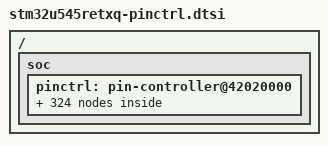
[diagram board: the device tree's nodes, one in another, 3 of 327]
/*
 * NOTE: Autogenerated file using genpinctrl.py
 *
 * SPDX-License-Identifier: Apache-2.0
 */

#include <zephyr/dt-bindings/pinctrl/stm32-pinctrl.h>

/ {
	soc {
		pinctrl: pin-controller@42020000 {

			/* ADC_IN / ADC_INN / ADC_INP */

			/omit-if-no-ref/ adc1_in5_pa0: adc1_in5_pa0 {
				pinmux = <STM32_PINMUX('A', 0, ANALOG)>;
			};

			/omit-if-no-ref/ adc1_in6_pa1: adc1_in6_pa1 {
				pinmux = <STM32_PINMUX('A', 1, ANALOG)>;
			};

			/omit-if-no-ref/ adc1_in7_pa2: adc1_in7_pa2 {
				pinmux = <STM32_PINMUX('A', 2, ANALOG)>;
			};

			/omit-if-no-ref/ adc1_in8_pa3: adc1_in8_pa3 {
				pinmux = <STM32_PINMUX('A', 3, ANALOG)>;
			};

			/omit-if-no-ref/ adc1_in9_pa4: adc1_in9_pa4 {
				pinmux = <STM32_PINMUX('A', 4, ANALOG)>;
			};

			/omit-if-no-ref/ adc1_in10_pa5: adc1_in10_pa5 {
				pinmux = <STM32_PINMUX('A', 5, ANALOG)>;
			};

			/omit-if-no-ref/ adc1_in11_pa6: adc1_in11_pa6 {
				pinmux = <STM32_PINMUX('A', 6, ANALOG)>;
			};

			/omit-if-no-ref/ adc1_in12_pa7: adc1_in12_pa7 {
				pinmux = <STM32_PINMUX('A', 7, ANALOG)>;
			};

			/omit-if-no-ref/ adc1_in15_pb0: adc1_in15_pb0 {
				pinmux = <STM32_PINMUX('B', 0, ANALOG)>;
			};

			/omit-if-no-ref/ adc1_in16_pb1: adc1_in16_pb1 {
				pinmux = <STM32_PINMUX('B', 1, ANALOG)>;
			};

			/omit-if-no-ref/ adc1_in17_pb2: adc1_in17_pb2 {
				pinmux = <STM32_PINMUX('B', 2, ANALOG)>;
			};

			/omit-if-no-ref/ adc1_in1_pc0: adc1_in1_pc0 {
				pinmux = <STM32_PINMUX('C', 0, ANALOG)>;
			};

			/omit-if-no-ref/ adc1_in2_pc1: adc1_in2_pc1 {
				pinmux = <STM32_PINMUX('C', 1, ANALOG)>;
			};

			/omit-if-no-ref/ adc1_in3_pc2: adc1_in3_pc2 {
				pinmux = <STM32_PINMUX('C', 2, ANALOG)>;
			};

			/omit-if-no-ref/ adc1_in4_pc3: adc1_in4_pc3 {
				pinmux = <STM32_PINMUX('C', 3, ANALOG)>;
			};

			/omit-if-no-ref/ adc4_in9_pa4: adc4_in9_pa4 {
				pinmux = <STM32_PINMUX('A', 4, ANALOG)>;
			};

			/omit-if-no-ref/ adc4_in10_pa5: adc4_in10_pa5 {
				pinmux = <STM32_PINMUX('A', 5, ANALOG)>;
			};

			/omit-if-no-ref/ adc4_in11_pa6: adc4_in11_pa6 {
				pinmux = <STM32_PINMUX('A', 6, ANALOG)>;
			};

			/omit-if-no-ref/ adc4_in20_pa7: adc4_in20_pa7 {
				pinmux = <STM32_PINMUX('A', 7, ANALOG)>;
			};

			/omit-if-no-ref/ adc4_in18_pb0: adc4_in18_pb0 {
				pinmux = <STM32_PINMUX('B', 0, ANALOG)>;
			};

			/omit-if-no-ref/ adc4_in19_pb1: adc4_in19_pb1 {
				pinmux = <STM32_PINMUX('B', 1, ANALOG)>;
			};

			/omit-if-no-ref/ adc4_in1_pc0: adc4_in1_pc0 {
				pinmux = <STM32_PINMUX('C', 0, ANALOG)>;
			};

			/omit-if-no-ref/ adc4_in2_pc1: adc4_in2_pc1 {
				pinmux = <STM32_PINMUX('C', 1, ANALOG)>;
			};

			/omit-if-no-ref/ adc4_in3_pc2: adc4_in3_pc2 {
				pinmux = <STM32_PINMUX('C', 2, ANALOG)>;
			};

			/omit-if-no-ref/ adc4_in4_pc3: adc4_in4_pc3 {
				pinmux = <STM32_PINMUX('C', 3, ANALOG)>;
			};

			/* Analog */

			/omit-if-no-ref/ analog_pa0: analog_pa0 {
				pinmux = <STM32_PINMUX('A', 0, ANALOG)>;
			};

			/omit-if-no-ref/ analog_pa1: analog_pa1 {
				pinmux = <STM32_PINMUX('A', 1, ANALOG)>;
			};

			/omit-if-no-ref/ analog_pa2: analog_pa2 {
				pinmux = <STM32_PINMUX('A', 2, ANALOG)>;
			};

			/omit-if-no-ref/ analog_pa3: analog_pa3 {
				pinmux = <STM32_PINMUX('A', 3, ANALOG)>;
			};

			/omit-if-no-ref/ analog_pa4: analog_pa4 {
				pinmux = <STM32_PINMUX('A', 4, ANALOG)>;
			};

			/omit-if-no-ref/ analog_pa5: analog_pa5 {
				pinmux = <STM32_PINMUX('A', 5, ANALOG)>;
			};

			/omit-if-no-ref/ analog_pa6: analog_pa6 {
				pinmux = <STM32_PINMUX('A', 6, ANALOG)>;
			};

			/omit-if-no-ref/ analog_pa7: analog_pa7 {
				pinmux = <STM32_PINMUX('A', 7, ANALOG)>;
			};

			/omit-if-no-ref/ analog_pa8: analog_pa8 {
				pinmux = <STM32_PINMUX('A', 8, ANALOG)>;
			};

			/omit-if-no-ref/ analog_pa9: analog_pa9 {
				pinmux = <STM32_PINMUX('A', 9, ANALOG)>;
			};

			/omit-if-no-ref/ analog_pa10: analog_pa10 {
				pinmux = <STM32_PINMUX('A', 10, ANALOG)>;
			};

			/omit-if-no-ref/ analog_pa11: analog_pa11 {
				pinmux = <STM32_PINMUX('A', 11, ANALOG)>;
			};

			/omit-if-no-ref/ analog_pa12: analog_pa12 {
				pinmux = <STM32_PINMUX('A', 12, ANALOG)>;
			};

			/omit-if-no-ref/ analog_pa13: analog_pa13 {
				pinmux = <STM32_PINMUX('A', 13, ANALOG)>;
			};

			/omit-if-no-ref/ analog_pa14: analog_pa14 {
				pinmux = <STM32_PINMUX('A', 14, ANALOG)>;
			};

			/omit-if-no-ref/ analog_pa15: analog_pa15 {
				pinmux = <STM32_PINMUX('A', 15, ANALOG)>;
			};

			/omit-if-no-ref/ analog_pb0: analog_pb0 {
				pinmux = <STM32_PINMUX('B', 0, ANALOG)>;
			};

			/omit-if-no-ref/ analog_pb1: analog_pb1 {
				pinmux = <STM32_PINMUX('B', 1, ANALOG)>;
			};

			/omit-if-no-ref/ analog_pb2: analog_pb2 {
				pinmux = <STM32_PINMUX('B', 2, ANALOG)>;
			};

			/omit-if-no-ref/ analog_pb3: analog_pb3 {
				pinmux = <STM32_PINMUX('B', 3, ANALOG)>;
			};

			/omit-if-no-ref/ analog_pb4: analog_pb4 {
				pinmux = <STM32_PINMUX('B', 4, ANALOG)>;
			};

			/omit-if-no-ref/ analog_pb5: analog_pb5 {
				pinmux = <STM32_PINMUX('B', 5, ANALOG)>;
			};

			/omit-if-no-ref/ analog_pb6: analog_pb6 {
				pinmux = <STM32_PINMUX('B', 6, ANALOG)>;
			};

			/omit-if-no-ref/ analog_pb7: analog_pb7 {
				pinmux = <STM32_PINMUX('B', 7, ANALOG)>;
			};

			/omit-if-no-ref/ analog_pb8: analog_pb8 {
				pinmux = <STM32_PINMUX('B', 8, ANALOG)>;
			};

			/omit-if-no-ref/ analog_pb10: analog_pb10 {
				pinmux = <STM32_PINMUX('B', 10, ANALOG)>;
			};

			/omit-if-no-ref/ analog_pb13: analog_pb13 {
				pinmux = <STM32_PINMUX('B', 13, ANALOG)>;
			};

			/omit-if-no-ref/ analog_pb14: analog_pb14 {
				pinmux = <STM32_PINMUX('B', 14, ANALOG)>;
			};

			/omit-if-no-ref/ analog_pb15: analog_pb15 {
				pinmux = <STM32_PINMUX('B', 15, ANALOG)>;
			};

			/omit-if-no-ref/ analog_pc0: analog_pc0 {
				pinmux = <STM32_PINMUX('C', 0, ANALOG)>;
			};

			/omit-if-no-ref/ analog_pc1: analog_pc1 {
				pinmux = <STM32_PINMUX('C', 1, ANALOG)>;
			};

			/omit-if-no-ref/ analog_pc2: analog_pc2 {
				pinmux = <STM32_PINMUX('C', 2, ANALOG)>;
			};

			/omit-if-no-ref/ analog_pc3: analog_pc3 {
				pinmux = <STM32_PINMUX('C', 3, ANALOG)>;
			};

			/omit-if-no-ref/ analog_pc6: analog_pc6 {
				pinmux = <STM32_PINMUX('C', 6, ANALOG)>;
			};

			/omit-if-no-ref/ analog_pc7: analog_pc7 {
				pinmux = <STM32_PINMUX('C', 7, ANALOG)>;
			};

			/omit-if-no-ref/ analog_pc8: analog_pc8 {
				pinmux = <STM32_PINMUX('C', 8, ANALOG)>;
			};

			/omit-if-no-ref/ analog_pc9: analog_pc9 {
				pinmux = <STM32_PINMUX('C', 9, ANALOG)>;
			};

			/omit-if-no-ref/ analog_pc10: analog_pc10 {
				pinmux = <STM32_PINMUX('C', 10, ANALOG)>;
			};

			/omit-if-no-ref/ analog_pc11: analog_pc11 {
				pinmux = <STM32_PINMUX('C', 11, ANALOG)>;
			};

			/omit-if-no-ref/ analog_pc12: analog_pc12 {
				pinmux = <STM32_PINMUX('C', 12, ANALOG)>;
			};

			/omit-if-no-ref/ analog_pc13: analog_pc13 {
				pinmux = <STM32_PINMUX('C', 13, ANALOG)>;
			};

			/omit-if-no-ref/ analog_pc14: analog_pc14 {
				pinmux = <STM32_PINMUX('C', 14, ANALOG)>;
			};

			/omit-if-no-ref/ analog_pc15: analog_pc15 {
				pinmux = <STM32_PINMUX('C', 15, ANALOG)>;
			};

			/omit-if-no-ref/ analog_pd2: analog_pd2 {
				pinmux = <STM32_PINMUX('D', 2, ANALOG)>;
			};

			/omit-if-no-ref/ analog_ph0: analog_ph0 {
				pinmux = <STM32_PINMUX('H', 0, ANALOG)>;
			};

			/omit-if-no-ref/ analog_ph1: analog_ph1 {
				pinmux = <STM32_PINMUX('H', 1, ANALOG)>;
			};

			/omit-if-no-ref/ analog_ph3: analog_ph3 {
				pinmux = <STM32_PINMUX('H', 3, ANALOG)>;
			};

			/* COMP_IN */

			/omit-if-no-ref/ comp1_inp_pa2: comp1_inp_pa2 {
				pinmux = <STM32_PINMUX('A', 2, ANALOG)>;
			};

			/omit-if-no-ref/ comp1_inm_pb1: comp1_inm_pb1 {
				pinmux = <STM32_PINMUX('B', 1, ANALOG)>;
			};

			/omit-if-no-ref/ comp1_inp_pb2: comp1_inp_pb2 {
				pinmux = <STM32_PINMUX('B', 2, ANALOG)>;
			};

			/omit-if-no-ref/ comp1_inp_pb3: comp1_inp_pb3 {
				pinmux = <STM32_PINMUX('B', 3, ANALOG)>;
			};

			/omit-if-no-ref/ comp1_inp_pb4: comp1_inp_pb4 {
				pinmux = <STM32_PINMUX('B', 4, ANALOG)>;
			};

			/omit-if-no-ref/ comp1_inp_pb6: comp1_inp_pb6 {
				pinmux = <STM32_PINMUX('B', 6, ANALOG)>;
			};

			/* COMP_OUT */

			/omit-if-no-ref/ comp1_out_pb0: comp1_out_pb0 {
				pinmux = <STM32_PINMUX('B', 0, AF12)>;
			};

			/omit-if-no-ref/ comp1_out_pb10: comp1_out_pb10 {
				pinmux = <STM32_PINMUX('B', 10, AF12)>;
			};

			/* DAC_OUT */

			/omit-if-no-ref/ dac1_out1_pa4: dac1_out1_pa4 {
				pinmux = <STM32_PINMUX('A', 4, ANALOG)>;
			};

			/omit-if-no-ref/ dac1_out2_pa5: dac1_out2_pa5 {
				pinmux = <STM32_PINMUX('A', 5, ANALOG)>;
			};

			/* FDCAN_RX */

			/omit-if-no-ref/ fdcan1_rx_pa11: fdcan1_rx_pa11 {
				pinmux = <STM32_PINMUX('A', 11, AF9)>;
			};

			/omit-if-no-ref/ fdcan1_rx_pb8: fdcan1_rx_pb8 {
				pinmux = <STM32_PINMUX('B', 8, AF9)>;
			};

			/* FDCAN_TX */

			/omit-if-no-ref/ fdcan1_tx_pa12: fdcan1_tx_pa12 {
				pinmux = <STM32_PINMUX('A', 12, AF9)>;
			};

			/* I2C_SCL */

			/omit-if-no-ref/ i2c1_scl_pb6: i2c1_scl_pb6 {
				pinmux = <STM32_PINMUX('B', 6, AF4)>;
				bias-pull-up;
				drive-open-drain;
			};

			/omit-if-no-ref/ i2c1_scl_pb8: i2c1_scl_pb8 {
				pinmux = <STM32_PINMUX('B', 8, AF4)>;
				bias-pull-up;
				drive-open-drain;
			};

			/omit-if-no-ref/ i2c2_scl_pb10: i2c2_scl_pb10 {
				pinmux = <STM32_PINMUX('B', 10, AF4)>;
				bias-pull-up;
				drive-open-drain;
			};

			/omit-if-no-ref/ i2c2_scl_pb13: i2c2_scl_pb13 {
				pinmux = <STM32_PINMUX('B', 13, AF4)>;
				bias-pull-up;
				drive-open-drain;
			};

			/omit-if-no-ref/ i2c3_scl_pa7: i2c3_scl_pa7 {
				pinmux = <STM32_PINMUX('A', 7, AF4)>;
				bias-pull-up;
				drive-open-drain;
			};

			/omit-if-no-ref/ i2c3_scl_pc0: i2c3_scl_pc0 {
				pinmux = <STM32_PINMUX('C', 0, AF4)>;
				bias-pull-up;
				drive-open-drain;
			};

			/omit-if-no-ref/ i2c4_scl_pb6: i2c4_scl_pb6 {
				pinmux = <STM32_PINMUX('B', 6, AF5)>;
				bias-pull-up;
				drive-open-drain;
			};

			/omit-if-no-ref/ i2c4_scl_pb10: i2c4_scl_pb10 {
				pinmux = <STM32_PINMUX('B', 10, AF3)>;
				bias-pull-up;
				drive-open-drain;
			};

			/* I2C_SDA */

			/omit-if-no-ref/ i2c1_sda_pb3: i2c1_sda_pb3 {
				pinmux = <STM32_PINMUX('B', 3, AF4)>;
				bias-pull-up;
				drive-open-drain;
			};

			/omit-if-no-ref/ i2c1_sda_pb7: i2c1_sda_pb7 {
				pinmux = <STM32_PINMUX('B', 7, AF4)>;
				bias-pull-up;
				drive-open-drain;
			};

			/omit-if-no-ref/ i2c2_sda_pb14: i2c2_sda_pb14 {
				pinmux = <STM32_PINMUX('B', 14, AF4)>;
				bias-pull-up;
				drive-open-drain;
			};

			/omit-if-no-ref/ i2c3_sda_pb4: i2c3_sda_pb4 {
				pinmux = <STM32_PINMUX('B', 4, AF4)>;
				bias-pull-up;
				drive-open-drain;
			};

			/omit-if-no-ref/ i2c3_sda_pc1: i2c3_sda_pc1 {
				pinmux = <STM32_PINMUX('C', 1, AF4)>;
				bias-pull-up;
				drive-open-drain;
			};

			/omit-if-no-ref/ i2c4_sda_pb7: i2c4_sda_pb7 {
				pinmux = <STM32_PINMUX('B', 7, AF5)>;
				bias-pull-up;
				drive-open-drain;
			};

			/* I2C_SMBA */

			/omit-if-no-ref/ i2c1_smba_pa1: i2c1_smba_pa1 {
				pinmux = <STM32_PINMUX('A', 1, AF4)>;
				bias-pull-up;
			};

			/omit-if-no-ref/ i2c1_smba_pa14: i2c1_smba_pa14 {
				pinmux = <STM32_PINMUX('A', 14, AF4)>;
				bias-pull-up;
			};

			/omit-if-no-ref/ i2c1_smba_pb5: i2c1_smba_pb5 {
				pinmux = <STM32_PINMUX('B', 5, AF4)>;
				bias-pull-up;
			};

			/omit-if-no-ref/ i2c3_smba_pb2: i2c3_smba_pb2 {
				pinmux = <STM32_PINMUX('B', 2, AF4)>;
				bias-pull-up;
			};

			/omit-if-no-ref/ i2c4_smba_pa14: i2c4_smba_pa14 {
				pinmux = <STM32_PINMUX('A', 14, AF5)>;
				bias-pull-up;
			};

			/* JTAG PORT */

			/omit-if-no-ref/ debug_jtms_swdio_pa13: debug_jtms_swdio_pa13 {
				pinmux = <STM32_PINMUX('A', 13, AF0)>;
			};

			/omit-if-no-ref/ debug_jtck_swclk_pa14: debug_jtck_swclk_pa14 {
				pinmux = <STM32_PINMUX('A', 14, AF0)>;
			};

			/omit-if-no-ref/ debug_jtdi_pa15: debug_jtdi_pa15 {
				pinmux = <STM32_PINMUX('A', 15, AF0)>;
			};

			/omit-if-no-ref/ debug_jtdo_swo_pb3: debug_jtdo_swo_pb3 {
				pinmux = <STM32_PINMUX('B', 3, AF0)>;
			};

			/omit-if-no-ref/ debug_jtrst_pb4: debug_jtrst_pb4 {
				pinmux = <STM32_PINMUX('B', 4, AF0)>;
			};

			/* OCTOSPI */

			/omit-if-no-ref/ octospi1_ncs_pa0: octospi1_ncs_pa0 {
				pinmux = <STM32_PINMUX('A', 0, AF10)>;
				slew-rate = "very-high-speed";
			};

			/omit-if-no-ref/ octospi1_dqs_pa1: octospi1_dqs_pa1 {
				pinmux = <STM32_PINMUX('A', 1, AF10)>;
				slew-rate = "very-high-speed";
			};

			/omit-if-no-ref/ octospi1_ncs_pa2: octospi1_ncs_pa2 {
				pinmux = <STM32_PINMUX('A', 2, AF10)>;
				slew-rate = "very-high-speed";
			};

			/omit-if-no-ref/ octospi1_clk_pa3: octospi1_clk_pa3 {
				pinmux = <STM32_PINMUX('A', 3, AF10)>;
				slew-rate = "very-high-speed";
			};

			/omit-if-no-ref/ octospi1_ncs_pa4: octospi1_ncs_pa4 {
				pinmux = <STM32_PINMUX('A', 4, AF3)>;
				slew-rate = "very-high-speed";
			};

			/omit-if-no-ref/ octospi1_io3_pa6: octospi1_io3_pa6 {
				pinmux = <STM32_PINMUX('A', 6, AF10)>;
				slew-rate = "very-high-speed";
			};

			/omit-if-no-ref/ octospi1_io2_pa7: octospi1_io2_pa7 {
				pinmux = <STM32_PINMUX('A', 7, AF10)>;
				slew-rate = "very-high-speed";
			};

			/omit-if-no-ref/ octospi1_ncs_pa12: octospi1_ncs_pa12 {
				pinmux = <STM32_PINMUX('A', 12, AF6)>;
				slew-rate = "very-high-speed";
			};

			/omit-if-no-ref/ octospi1_io1_pb0: octospi1_io1_pb0 {
				pinmux = <STM32_PINMUX('B', 0, AF10)>;
				slew-rate = "very-high-speed";
			};

			/omit-if-no-ref/ octospi1_io0_pb1: octospi1_io0_pb1 {
				pinmux = <STM32_PINMUX('B', 1, AF10)>;
				slew-rate = "very-high-speed";
			};

			/omit-if-no-ref/ octospi1_dqs_pb2: octospi1_dqs_pb2 {
				pinmux = <STM32_PINMUX('B', 2, AF10)>;
				slew-rate = "very-high-speed";
			};

			/omit-if-no-ref/ octospi1_nclk_pb5: octospi1_nclk_pb5 {
				pinmux = <STM32_PINMUX('B', 5, AF3)>;
				slew-rate = "very-high-speed";
			};

			/omit-if-no-ref/ octospi1_clk_pb10: octospi1_clk_pb10 {
				pinmux = <STM32_PINMUX('B', 10, AF10)>;
				slew-rate = "very-high-speed";
			};

			/omit-if-no-ref/ octospi1_io7_pc0: octospi1_io7_pc0 {
				pinmux = <STM32_PINMUX('C', 0, AF3)>;
				slew-rate = "very-high-speed";
			};

			/omit-if-no-ref/ octospi1_io4_pc1: octospi1_io4_pc1 {
				pinmux = <STM32_PINMUX('C', 1, AF10)>;
				slew-rate = "very-high-speed";
			};

			/omit-if-no-ref/ octospi1_io5_pc2: octospi1_io5_pc2 {
				pinmux = <STM32_PINMUX('C', 2, AF10)>;
				slew-rate = "very-high-speed";
			};

			/omit-if-no-ref/ octospi1_io6_pc3: octospi1_io6_pc3 {
				pinmux = <STM32_PINMUX('C', 3, AF10)>;
				slew-rate = "very-high-speed";
			};

			/omit-if-no-ref/ octospi1_ncs_pc11: octospi1_ncs_pc11 {
				pinmux = <STM32_PINMUX('C', 11, AF5)>;
				slew-rate = "very-high-speed";
			};

			/* OPAMP */

			/omit-if-no-ref/ opamp1_vinp_pa0: opamp1_vinp_pa0 {
				pinmux = <STM32_PINMUX('A', 0, ANALOG)>;
			};

			/omit-if-no-ref/ opamp1_vinm_pa1: opamp1_vinm_pa1 {
				pinmux = <STM32_PINMUX('A', 1, ANALOG)>;
			};

			/omit-if-no-ref/ opamp1_vout_pa3: opamp1_vout_pa3 {
				pinmux = <STM32_PINMUX('A', 3, ANALOG)>;
			};

			/* RCC_MCO */

			/omit-if-no-ref/ rcc_mco_pa8: rcc_mco_pa8 {
				pinmux = <STM32_PINMUX('A', 8, AF0)>;
				slew-rate = "very-high-speed";
			};

			/* SAI */

			/omit-if-no-ref/ sai1_ck1_pa3: sai1_ck1_pa3 {
				pinmux = <STM32_PINMUX('A', 3, AF3)>;
			};

			/omit-if-no-ref/ sai1_mclk_a_pa3: sai1_mclk_a_pa3 {
				pinmux = <STM32_PINMUX('A', 3, AF13)>;
			};

			/omit-if-no-ref/ sai1_fs_b_pa4: sai1_fs_b_pa4 {
				pinmux = <STM32_PINMUX('A', 4, AF13)>;
			};

			/omit-if-no-ref/ sai1_ck2_pa8: sai1_ck2_pa8 {
				pinmux = <STM32_PINMUX('A', 8, AF3)>;
			};

			/omit-if-no-ref/ sai1_sck_a_pa8: sai1_sck_a_pa8 {
				pinmux = <STM32_PINMUX('A', 8, AF13)>;
			};

			/omit-if-no-ref/ sai1_fs_a_pa9: sai1_fs_a_pa9 {
				pinmux = <STM32_PINMUX('A', 9, AF13)>;
			};

			/omit-if-no-ref/ sai1_d1_pa10: sai1_d1_pa10 {
				pinmux = <STM32_PINMUX('A', 10, AF3)>;
			};

			/omit-if-no-ref/ sai1_sd_a_pa10: sai1_sd_a_pa10 {
				pinmux = <STM32_PINMUX('A', 10, AF13)>;
			};

			/omit-if-no-ref/ sai1_sd_b_pa13: sai1_sd_b_pa13 {
				pinmux = <STM32_PINMUX('A', 13, AF13)>;
			};

			/omit-if-no-ref/ sai1_fs_b_pa14: sai1_fs_b_pa14 {
				pinmux = <STM32_PINMUX('A', 14, AF13)>;
			};

			/omit-if-no-ref/ sai1_sck_b_pb3: sai1_sck_b_pb3 {
				pinmux = <STM32_PINMUX('B', 3, AF13)>;
			};

			/omit-if-no-ref/ sai1_mclk_b_pb4: sai1_mclk_b_pb4 {
				pinmux = <STM32_PINMUX('B', 4, AF13)>;
			};

			/omit-if-no-ref/ sai1_sd_b_pb5: sai1_sd_b_pb5 {
				pinmux = <STM32_PINMUX('B', 5, AF13)>;
			};

			/omit-if-no-ref/ sai1_fs_b_pb6: sai1_fs_b_pb6 {
				pinmux = <STM32_PINMUX('B', 6, AF13)>;
			};

			/omit-if-no-ref/ sai1_ck1_pb8: sai1_ck1_pb8 {
				pinmux = <STM32_PINMUX('B', 8, AF3)>;
			};

			/omit-if-no-ref/ sai1_mclk_a_pb8: sai1_mclk_a_pb8 {
				pinmux = <STM32_PINMUX('B', 8, AF13)>;
			};

			/omit-if-no-ref/ sai1_sck_a_pb10: sai1_sck_a_pb10 {
				pinmux = <STM32_PINMUX('B', 10, AF13)>;
			};

			/omit-if-no-ref/ sai1_sd_a_pc1: sai1_sd_a_pc1 {
				pinmux = <STM32_PINMUX('C', 1, AF13)>;
			};

			/omit-if-no-ref/ sai1_d1_pc3: sai1_d1_pc3 {
				pinmux = <STM32_PINMUX('C', 3, AF3)>;
			};

			/omit-if-no-ref/ sai1_sd_a_pc3: sai1_sd_a_pc3 {
				pinmux = <STM32_PINMUX('C', 3, AF13)>;
			};

			/* SDMMC */

			/omit-if-no-ref/ sdmmc1_ckin_pb8: sdmmc1_ckin_pb8 {
				pinmux = <STM32_PINMUX('B', 8, AF8)>;
				bias-pull-up;
				slew-rate = "very-high-speed";
			};

			/omit-if-no-ref/ sdmmc1_d4_pb8: sdmmc1_d4_pb8 {
				pinmux = <STM32_PINMUX('B', 8, AF12)>;
				bias-pull-up;
				slew-rate = "very-high-speed";
			};

			/omit-if-no-ref/ sdmmc1_d5_pc0: sdmmc1_d5_pc0 {
				pinmux = <STM32_PINMUX('C', 0, AF12)>;
				bias-pull-up;
				slew-rate = "very-high-speed";
			};

			/omit-if-no-ref/ sdmmc1_d0dir_pc6: sdmmc1_d0dir_pc6 {
				pinmux = <STM32_PINMUX('C', 6, AF8)>;
				bias-pull-up;
				slew-rate = "very-high-speed";
			};

			/omit-if-no-ref/ sdmmc1_d6_pc6: sdmmc1_d6_pc6 {
				pinmux = <STM32_PINMUX('C', 6, AF12)>;
				bias-pull-up;
				slew-rate = "very-high-speed";
			};

			/omit-if-no-ref/ sdmmc1_d123dir_pc7: sdmmc1_d123dir_pc7 {
				pinmux = <STM32_PINMUX('C', 7, AF8)>;
				bias-pull-up;
				slew-rate = "very-high-speed";
			};

			/omit-if-no-ref/ sdmmc1_d7_pc7: sdmmc1_d7_pc7 {
				pinmux = <STM32_PINMUX('C', 7, AF12)>;
				bias-pull-up;
				slew-rate = "very-high-speed";
			};

			/omit-if-no-ref/ sdmmc1_d0_pc8: sdmmc1_d0_pc8 {
				pinmux = <STM32_PINMUX('C', 8, AF12)>;
				bias-pull-up;
				slew-rate = "very-high-speed";
			};

			/omit-if-no-ref/ sdmmc1_d1_pc9: sdmmc1_d1_pc9 {
				pinmux = <STM32_PINMUX('C', 9, AF12)>;
				bias-pull-up;
				slew-rate = "very-high-speed";
			};

			/omit-if-no-ref/ sdmmc1_d2_pc10: sdmmc1_d2_pc10 {
				pinmux = <STM32_PINMUX('C', 10, AF12)>;
				bias-pull-up;
				slew-rate = "very-high-speed";
			};

			/omit-if-no-ref/ sdmmc1_d3_pc11: sdmmc1_d3_pc11 {
				pinmux = <STM32_PINMUX('C', 11, AF12)>;
				bias-pull-up;
				slew-rate = "very-high-speed";
			};

			/omit-if-no-ref/ sdmmc1_ck_pc12: sdmmc1_ck_pc12 {
				pinmux = <STM32_PINMUX('C', 12, AF12)>;
				bias-pull-up;
				slew-rate = "very-high-speed";
			};

			/omit-if-no-ref/ sdmmc1_cmd_pd2: sdmmc1_cmd_pd2 {
				pinmux = <STM32_PINMUX('D', 2, AF12)>;
				bias-pull-up;
				slew-rate = "very-high-speed";
			};

			/* SPI_MISO */

			/omit-if-no-ref/ spi1_miso_pa6: spi1_miso_pa6 {
				pinmux = <STM32_PINMUX('A', 6, AF5)>;
				bias-pull-down;
			};

			/omit-if-no-ref/ spi1_miso_pa11: spi1_miso_pa11 {
				pinmux = <STM32_PINMUX('A', 11, AF5)>;
				bias-pull-down;
			};

			/omit-if-no-ref/ spi1_miso_pb4: spi1_miso_pb4 {
				pinmux = <STM32_PINMUX('B', 4, AF5)>;
				bias-pull-down;
			};

			/omit-if-no-ref/ spi2_miso_pb14: spi2_miso_pb14 {
				pinmux = <STM32_PINMUX('B', 14, AF5)>;
				bias-pull-down;
			};

			/omit-if-no-ref/ spi2_miso_pc2: spi2_miso_pc2 {
				pinmux = <STM32_PINMUX('C', 2, AF5)>;
				bias-pull-down;
			};

			/omit-if-no-ref/ spi3_miso_pb4: spi3_miso_pb4 {
				pinmux = <STM32_PINMUX('B', 4, AF6)>;
				bias-pull-down;
			};

			/omit-if-no-ref/ spi3_miso_pc11: spi3_miso_pc11 {
				pinmux = <STM32_PINMUX('C', 11, AF6)>;
				bias-pull-down;
			};

			/* SPI_MOSI */

			/omit-if-no-ref/ spi1_mosi_pa7: spi1_mosi_pa7 {
				pinmux = <STM32_PINMUX('A', 7, AF5)>;
				bias-pull-down;
			};

			/omit-if-no-ref/ spi1_mosi_pa12: spi1_mosi_pa12 {
				pinmux = <STM32_PINMUX('A', 12, AF5)>;
				bias-pull-down;
			};

			/omit-if-no-ref/ spi1_mosi_pb5: spi1_mosi_pb5 {
				pinmux = <STM32_PINMUX('B', 5, AF5)>;
				bias-pull-down;
			};

			/omit-if-no-ref/ spi2_mosi_pb15: spi2_mosi_pb15 {
				pinmux = <STM32_PINMUX('B', 15, AF5)>;
				bias-pull-down;
			};

			/omit-if-no-ref/ spi2_mosi_pc1: spi2_mosi_pc1 {
				pinmux = <STM32_PINMUX('C', 1, AF3)>;
				bias-pull-down;
			};

			/omit-if-no-ref/ spi2_mosi_pc3: spi2_mosi_pc3 {
				pinmux = <STM32_PINMUX('C', 3, AF5)>;
				bias-pull-down;
			};

			/omit-if-no-ref/ spi3_mosi_pb5: spi3_mosi_pb5 {
				pinmux = <STM32_PINMUX('B', 5, AF6)>;
				bias-pull-down;
			};

			/omit-if-no-ref/ spi3_mosi_pc12: spi3_mosi_pc12 {
				pinmux = <STM32_PINMUX('C', 12, AF6)>;
				bias-pull-down;
			};

			/* SPI_NSS */

			/omit-if-no-ref/ spi1_nss_pa4: spi1_nss_pa4 {
				pinmux = <STM32_PINMUX('A', 4, AF5)>;
				bias-pull-up;
			};

			/omit-if-no-ref/ spi1_nss_pa15: spi1_nss_pa15 {
				pinmux = <STM32_PINMUX('A', 15, AF5)>;
				bias-pull-up;
			};

			/omit-if-no-ref/ spi1_nss_pb0: spi1_nss_pb0 {
				pinmux = <STM32_PINMUX('B', 0, AF5)>;
				bias-pull-up;
			};

			/omit-if-no-ref/ spi3_nss_pa4: spi3_nss_pa4 {
				pinmux = <STM32_PINMUX('A', 4, AF6)>;
				bias-pull-up;
			};

			/omit-if-no-ref/ spi3_nss_pa15: spi3_nss_pa15 {
				pinmux = <STM32_PINMUX('A', 15, AF6)>;
				bias-pull-up;
			};

			/* SPI_SCK */

			/omit-if-no-ref/ spi1_sck_pa1: spi1_sck_pa1 {
				pinmux = <STM32_PINMUX('A', 1, AF5)>;
				bias-pull-down;
				slew-rate = "very-high-speed";
			};

			/omit-if-no-ref/ spi1_sck_pa5: spi1_sck_pa5 {
				pinmux = <STM32_PINMUX('A', 5, AF5)>;
				bias-pull-down;
				slew-rate = "very-high-speed";
			};

			/omit-if-no-ref/ spi1_sck_pb3: spi1_sck_pb3 {
				pinmux = <STM32_PINMUX('B', 3, AF5)>;
				bias-pull-down;
				slew-rate = "very-high-speed";
			};

			/omit-if-no-ref/ spi2_sck_pa9: spi2_sck_pa9 {
				pinmux = <STM32_PINMUX('A', 9, AF3)>;
				bias-pull-down;
				slew-rate = "very-high-speed";
			};

			/omit-if-no-ref/ spi2_sck_pb10: spi2_sck_pb10 {
				pinmux = <STM32_PINMUX('B', 10, AF5)>;
				bias-pull-down;
				slew-rate = "very-high-speed";
			};

			/omit-if-no-ref/ spi2_sck_pb13: spi2_sck_pb13 {
				pinmux = <STM32_PINMUX('B', 13, AF5)>;
				bias-pull-down;
				slew-rate = "very-high-speed";
			};

			/omit-if-no-ref/ spi3_sck_pb3: spi3_sck_pb3 {
				pinmux = <STM32_PINMUX('B', 3, AF6)>;
				bias-pull-down;
				slew-rate = "very-high-speed";
			};

			/omit-if-no-ref/ spi3_sck_pc10: spi3_sck_pc10 {
				pinmux = <STM32_PINMUX('C', 10, AF6)>;
				bias-pull-down;
				slew-rate = "very-high-speed";
			};

			/* TIM_BKIN */

			/omit-if-no-ref/ tim1_bkin_pa6: tim1_bkin_pa6 {
				pinmux = <STM32_PINMUX('A', 6, AF1)>;
			};

			/omit-if-no-ref/ tim1_bkin2_pa11: tim1_bkin2_pa11 {
				pinmux = <STM32_PINMUX('A', 11, AF2)>;
			};

			/omit-if-no-ref/ tim15_bkin_pa9: tim15_bkin_pa9 {
				pinmux = <STM32_PINMUX('A', 9, AF14)>;
			};

			/omit-if-no-ref/ tim16_bkin_pb5: tim16_bkin_pb5 {
				pinmux = <STM32_PINMUX('B', 5, AF14)>;
			};

			/omit-if-no-ref/ tim17_bkin_pa10: tim17_bkin_pa10 {
				pinmux = <STM32_PINMUX('A', 10, AF14)>;
			};

			/omit-if-no-ref/ tim17_bkin_pb4: tim17_bkin_pb4 {
				pinmux = <STM32_PINMUX('B', 4, AF14)>;
			};

			/omit-if-no-ref/ tim8_bkin_pa6: tim8_bkin_pa6 {
				pinmux = <STM32_PINMUX('A', 6, AF3)>;
			};

			/omit-if-no-ref/ tim8_bkin2_pb6: tim8_bkin2_pb6 {
				pinmux = <STM32_PINMUX('B', 6, AF3)>;
			};

			/omit-if-no-ref/ tim8_bkin_pb7: tim8_bkin_pb7 {
				pinmux = <STM32_PINMUX('B', 7, AF3)>;
			};

			/omit-if-no-ref/ tim8_bkin2_pc9: tim8_bkin2_pc9 {
				pinmux = <STM32_PINMUX('C', 9, AF1)>;
			};

			/* TIM_CH / TIM_CHN */

			/omit-if-no-ref/ tim1_ch1n_pa7: tim1_ch1n_pa7 {
				pinmux = <STM32_PINMUX('A', 7, AF1)>;
			};

			/omit-if-no-ref/ tim1_ch1_pa8: tim1_ch1_pa8 {
				pinmux = <STM32_PINMUX('A', 8, AF1)>;
			};

			/omit-if-no-ref/ tim1_ch2_pa9: tim1_ch2_pa9 {
				pinmux = <STM32_PINMUX('A', 9, AF1)>;
			};

			/omit-if-no-ref/ tim1_ch3_pa10: tim1_ch3_pa10 {
				pinmux = <STM32_PINMUX('A', 10, AF1)>;
			};

			/omit-if-no-ref/ tim1_ch4_pa11: tim1_ch4_pa11 {
				pinmux = <STM32_PINMUX('A', 11, AF1)>;
			};

			/omit-if-no-ref/ tim1_ch2n_pb0: tim1_ch2n_pb0 {
				pinmux = <STM32_PINMUX('B', 0, AF1)>;
			};

			/omit-if-no-ref/ tim1_ch3n_pb1: tim1_ch3n_pb1 {
				pinmux = <STM32_PINMUX('B', 1, AF1)>;
			};

			/omit-if-no-ref/ tim1_ch1n_pb13: tim1_ch1n_pb13 {
				pinmux = <STM32_PINMUX('B', 13, AF1)>;
			};

			/omit-if-no-ref/ tim1_ch2n_pb14: tim1_ch2n_pb14 {
				pinmux = <STM32_PINMUX('B', 14, AF1)>;
			};

			/omit-if-no-ref/ tim1_ch3n_pb15: tim1_ch3n_pb15 {
				pinmux = <STM32_PINMUX('B', 15, AF1)>;
			};

			/omit-if-no-ref/ tim2_ch1_pa0: tim2_ch1_pa0 {
				pinmux = <STM32_PINMUX('A', 0, AF1)>;
			};

			/omit-if-no-ref/ tim2_ch2_pa1: tim2_ch2_pa1 {
				pinmux = <STM32_PINMUX('A', 1, AF1)>;
			};

			/omit-if-no-ref/ tim2_ch3_pa2: tim2_ch3_pa2 {
				pinmux = <STM32_PINMUX('A', 2, AF1)>;
			};

			/omit-if-no-ref/ tim2_ch4_pa3: tim2_ch4_pa3 {
				pinmux = <STM32_PINMUX('A', 3, AF1)>;
			};

			/omit-if-no-ref/ tim2_ch1_pa5: tim2_ch1_pa5 {
				pinmux = <STM32_PINMUX('A', 5, AF1)>;
			};

			/omit-if-no-ref/ tim2_ch1_pa15: tim2_ch1_pa15 {
				pinmux = <STM32_PINMUX('A', 15, AF1)>;
			};

			/omit-if-no-ref/ tim2_ch2_pb3: tim2_ch2_pb3 {
				pinmux = <STM32_PINMUX('B', 3, AF1)>;
			};

			/omit-if-no-ref/ tim2_ch3_pb10: tim2_ch3_pb10 {
				pinmux = <STM32_PINMUX('B', 10, AF1)>;
			};

			/omit-if-no-ref/ tim3_ch1_pa6: tim3_ch1_pa6 {
				pinmux = <STM32_PINMUX('A', 6, AF2)>;
			};

			/omit-if-no-ref/ tim3_ch2_pa7: tim3_ch2_pa7 {
				pinmux = <STM32_PINMUX('A', 7, AF2)>;
			};

			/omit-if-no-ref/ tim3_ch3_pb0: tim3_ch3_pb0 {
				pinmux = <STM32_PINMUX('B', 0, AF2)>;
			};

			/omit-if-no-ref/ tim3_ch4_pb1: tim3_ch4_pb1 {
				pinmux = <STM32_PINMUX('B', 1, AF2)>;
			};

			/omit-if-no-ref/ tim3_ch1_pb4: tim3_ch1_pb4 {
				pinmux = <STM32_PINMUX('B', 4, AF2)>;
			};

			/omit-if-no-ref/ tim3_ch2_pb5: tim3_ch2_pb5 {
				pinmux = <STM32_PINMUX('B', 5, AF2)>;
			};

			/omit-if-no-ref/ tim3_ch1_pc6: tim3_ch1_pc6 {
				pinmux = <STM32_PINMUX('C', 6, AF2)>;
			};

			/omit-if-no-ref/ tim3_ch2_pc7: tim3_ch2_pc7 {
				pinmux = <STM32_PINMUX('C', 7, AF2)>;
			};

			/omit-if-no-ref/ tim3_ch3_pc8: tim3_ch3_pc8 {
				pinmux = <STM32_PINMUX('C', 8, AF2)>;
			};

			/omit-if-no-ref/ tim3_ch4_pc9: tim3_ch4_pc9 {
				pinmux = <STM32_PINMUX('C', 9, AF2)>;
			};

			/omit-if-no-ref/ tim4_ch1_pb6: tim4_ch1_pb6 {
				pinmux = <STM32_PINMUX('B', 6, AF2)>;
			};

			/omit-if-no-ref/ tim4_ch2_pb7: tim4_ch2_pb7 {
				pinmux = <STM32_PINMUX('B', 7, AF2)>;
			};

			/omit-if-no-ref/ tim4_ch3_pb8: tim4_ch3_pb8 {
				pinmux = <STM32_PINMUX('B', 8, AF2)>;
			};

			/omit-if-no-ref/ tim5_ch1_pa0: tim5_ch1_pa0 {
				pinmux = <STM32_PINMUX('A', 0, AF2)>;
			};

			/omit-if-no-ref/ tim15_ch1n_pa1: tim15_ch1n_pa1 {
				pinmux = <STM32_PINMUX('A', 1, AF14)>;
			};

			/omit-if-no-ref/ tim5_ch2_pa1: tim5_ch2_pa1 {
				pinmux = <STM32_PINMUX('A', 1, AF2)>;
			};

			/omit-if-no-ref/ tim15_ch1_pa2: tim15_ch1_pa2 {
				pinmux = <STM32_PINMUX('A', 2, AF14)>;
			};

			/omit-if-no-ref/ tim5_ch3_pa2: tim5_ch3_pa2 {
				pinmux = <STM32_PINMUX('A', 2, AF2)>;
			};

			/omit-if-no-ref/ tim15_ch2_pa3: tim15_ch2_pa3 {
				pinmux = <STM32_PINMUX('A', 3, AF14)>;
			};

			/omit-if-no-ref/ tim5_ch4_pa3: tim5_ch4_pa3 {
				pinmux = <STM32_PINMUX('A', 3, AF2)>;
			};

			/omit-if-no-ref/ tim15_ch1n_pb13: tim15_ch1n_pb13 {
				pinmux = <STM32_PINMUX('B', 13, AF14)>;
			};

			/omit-if-no-ref/ tim15_ch1_pb14: tim15_ch1_pb14 {
				pinmux = <STM32_PINMUX('B', 14, AF14)>;
			};

			/omit-if-no-ref/ tim15_ch2_pb15: tim15_ch2_pb15 {
				pinmux = <STM32_PINMUX('B', 15, AF14)>;
			};

			/omit-if-no-ref/ tim16_ch1_pa6: tim16_ch1_pa6 {
				pinmux = <STM32_PINMUX('A', 6, AF14)>;
			};

			/omit-if-no-ref/ tim16_ch1n_pb6: tim16_ch1n_pb6 {
				pinmux = <STM32_PINMUX('B', 6, AF14)>;
			};

			/omit-if-no-ref/ tim16_ch1_pb8: tim16_ch1_pb8 {
				pinmux = <STM32_PINMUX('B', 8, AF14)>;
			};

			/omit-if-no-ref/ tim17_ch1_pa7: tim17_ch1_pa7 {
				pinmux = <STM32_PINMUX('A', 7, AF14)>;
			};

			/omit-if-no-ref/ tim17_ch1n_pb7: tim17_ch1n_pb7 {
				pinmux = <STM32_PINMUX('B', 7, AF14)>;
			};

			/omit-if-no-ref/ tim8_ch1n_pa5: tim8_ch1n_pa5 {
				pinmux = <STM32_PINMUX('A', 5, AF3)>;
			};

			/omit-if-no-ref/ tim8_ch1n_pa7: tim8_ch1n_pa7 {
				pinmux = <STM32_PINMUX('A', 7, AF3)>;
			};

			/omit-if-no-ref/ tim8_ch2n_pb0: tim8_ch2n_pb0 {
				pinmux = <STM32_PINMUX('B', 0, AF3)>;
			};

			/omit-if-no-ref/ tim8_ch3n_pb1: tim8_ch3n_pb1 {
				pinmux = <STM32_PINMUX('B', 1, AF3)>;
			};

			/omit-if-no-ref/ tim8_ch4n_pb2: tim8_ch4n_pb2 {
				pinmux = <STM32_PINMUX('B', 2, AF3)>;
			};

			/omit-if-no-ref/ tim8_ch2n_pb14: tim8_ch2n_pb14 {
				pinmux = <STM32_PINMUX('B', 14, AF3)>;
			};

			/omit-if-no-ref/ tim8_ch3n_pb15: tim8_ch3n_pb15 {
				pinmux = <STM32_PINMUX('B', 15, AF3)>;
			};

			/omit-if-no-ref/ tim8_ch1_pc6: tim8_ch1_pc6 {
				pinmux = <STM32_PINMUX('C', 6, AF3)>;
			};

			/omit-if-no-ref/ tim8_ch2_pc7: tim8_ch2_pc7 {
				pinmux = <STM32_PINMUX('C', 7, AF3)>;
			};

			/omit-if-no-ref/ tim8_ch3_pc8: tim8_ch3_pc8 {
				pinmux = <STM32_PINMUX('C', 8, AF3)>;
			};

			/omit-if-no-ref/ tim8_ch4_pc9: tim8_ch4_pc9 {
				pinmux = <STM32_PINMUX('C', 9, AF3)>;
			};

			/* TSC */

			/omit-if-no-ref/ tsc_g2_io1_pb4: tsc_g2_io1_pb4 {
				pinmux = <STM32_PINMUX('B', 4, AF9)>;
			};

			/omit-if-no-ref/ tsc_g2_io2_pb5: tsc_g2_io2_pb5 {
				pinmux = <STM32_PINMUX('B', 5, AF9)>;
			};

			/omit-if-no-ref/ tsc_g2_io3_pb6: tsc_g2_io3_pb6 {
				pinmux = <STM32_PINMUX('B', 6, AF9)>;
			};

			/omit-if-no-ref/ tsc_g2_io4_pb7: tsc_g2_io4_pb7 {
				pinmux = <STM32_PINMUX('B', 7, AF9)>;
			};

			/omit-if-no-ref/ tsc_sync_pb10: tsc_sync_pb10 {
				pinmux = <STM32_PINMUX('B', 10, AF9)>;
			};

			/omit-if-no-ref/ tsc_g1_io2_pb13: tsc_g1_io2_pb13 {
				pinmux = <STM32_PINMUX('B', 13, AF9)>;
			};

			/omit-if-no-ref/ tsc_g1_io3_pb14: tsc_g1_io3_pb14 {
				pinmux = <STM32_PINMUX('B', 14, AF9)>;
			};

			/omit-if-no-ref/ tsc_g4_io1_pc6: tsc_g4_io1_pc6 {
				pinmux = <STM32_PINMUX('C', 6, AF9)>;
			};

			/omit-if-no-ref/ tsc_g4_io2_pc7: tsc_g4_io2_pc7 {
				pinmux = <STM32_PINMUX('C', 7, AF9)>;
			};

			/omit-if-no-ref/ tsc_g4_io3_pc8: tsc_g4_io3_pc8 {
				pinmux = <STM32_PINMUX('C', 8, AF9)>;
			};

			/omit-if-no-ref/ tsc_g4_io4_pc9: tsc_g4_io4_pc9 {
				pinmux = <STM32_PINMUX('C', 9, AF9)>;
			};

			/omit-if-no-ref/ tsc_g3_io2_pc10: tsc_g3_io2_pc10 {
				pinmux = <STM32_PINMUX('C', 10, AF9)>;
			};

			/omit-if-no-ref/ tsc_g3_io3_pc11: tsc_g3_io3_pc11 {
				pinmux = <STM32_PINMUX('C', 11, AF9)>;
			};

			/omit-if-no-ref/ tsc_g3_io4_pc12: tsc_g3_io4_pc12 {
				pinmux = <STM32_PINMUX('C', 12, AF9)>;
			};

			/omit-if-no-ref/ tsc_sync_pd2: tsc_sync_pd2 {
				pinmux = <STM32_PINMUX('D', 2, AF9)>;
			};

			/* UART_CTS / USART_CTS / LPUART_CTS */

			/omit-if-no-ref/ lpuart1_cts_pa6: lpuart1_cts_pa6 {
				pinmux = <STM32_PINMUX('A', 6, AF8)>;
				bias-pull-up;
			};

			/omit-if-no-ref/ usart1_cts_pa11: usart1_cts_pa11 {
				pinmux = <STM32_PINMUX('A', 11, AF7)>;
				bias-pull-up;
			};

			/omit-if-no-ref/ usart1_cts_pb4: usart1_cts_pb4 {
				pinmux = <STM32_PINMUX('B', 4, AF7)>;
				bias-pull-up;
			};

			/omit-if-no-ref/ lpuart1_cts_pb13: lpuart1_cts_pb13 {
				pinmux = <STM32_PINMUX('B', 13, AF8)>;
				bias-pull-up;
			};

			/omit-if-no-ref/ usart3_cts_pa6: usart3_cts_pa6 {
				pinmux = <STM32_PINMUX('A', 6, AF7)>;
				bias-pull-up;
			};

			/omit-if-no-ref/ usart3_cts_pb13: usart3_cts_pb13 {
				pinmux = <STM32_PINMUX('B', 13, AF7)>;
				bias-pull-up;
			};

			/omit-if-no-ref/ uart4_cts_pb7: uart4_cts_pb7 {
				pinmux = <STM32_PINMUX('B', 7, AF8)>;
				bias-pull-up;
			};

			/omit-if-no-ref/ uart5_cts_pb5: uart5_cts_pb5 {
				pinmux = <STM32_PINMUX('B', 5, AF8)>;
				bias-pull-up;
			};

			/* UART_DE / USART_DE / LPUART_DE */

			/omit-if-no-ref/ usart1_de_pa12: usart1_de_pa12 {
				pinmux = <STM32_PINMUX('A', 12, AF7)>;
				drive-push-pull;
			};

			/omit-if-no-ref/ lpuart1_de_pb1: lpuart1_de_pb1 {
				pinmux = <STM32_PINMUX('B', 1, AF8)>;
				drive-push-pull;
			};

			/omit-if-no-ref/ usart1_de_pb3: usart1_de_pb3 {
				pinmux = <STM32_PINMUX('B', 3, AF7)>;
				drive-push-pull;
			};

			/omit-if-no-ref/ usart3_de_pa15: usart3_de_pa15 {
				pinmux = <STM32_PINMUX('A', 15, AF7)>;
				drive-push-pull;
			};

			/omit-if-no-ref/ usart3_de_pb1: usart3_de_pb1 {
				pinmux = <STM32_PINMUX('B', 1, AF7)>;
				drive-push-pull;
			};

			/omit-if-no-ref/ usart3_de_pb14: usart3_de_pb14 {
				pinmux = <STM32_PINMUX('B', 14, AF7)>;
				drive-push-pull;
			};

			/omit-if-no-ref/ usart3_de_pd2: usart3_de_pd2 {
				pinmux = <STM32_PINMUX('D', 2, AF7)>;
				drive-push-pull;
			};

			/omit-if-no-ref/ uart4_de_pa15: uart4_de_pa15 {
				pinmux = <STM32_PINMUX('A', 15, AF8)>;
				drive-push-pull;
			};

			/omit-if-no-ref/ uart5_de_pb4: uart5_de_pb4 {
				pinmux = <STM32_PINMUX('B', 4, AF8)>;
				drive-push-pull;
			};

			/* UART_RTS / USART_RTS / LPUART_RTS */

			/omit-if-no-ref/ usart1_rts_pa12: usart1_rts_pa12 {
				pinmux = <STM32_PINMUX('A', 12, AF7)>;
				drive-push-pull;
			};

			/omit-if-no-ref/ lpuart1_rts_pb1: lpuart1_rts_pb1 {
				pinmux = <STM32_PINMUX('B', 1, AF8)>;
				drive-push-pull;
			};

			/omit-if-no-ref/ usart1_rts_pb3: usart1_rts_pb3 {
				pinmux = <STM32_PINMUX('B', 3, AF7)>;
				drive-push-pull;
			};

			/omit-if-no-ref/ usart3_rts_pa15: usart3_rts_pa15 {
				pinmux = <STM32_PINMUX('A', 15, AF7)>;
				drive-push-pull;
			};

			/omit-if-no-ref/ usart3_rts_pb1: usart3_rts_pb1 {
				pinmux = <STM32_PINMUX('B', 1, AF7)>;
				drive-push-pull;
			};

			/omit-if-no-ref/ usart3_rts_pb14: usart3_rts_pb14 {
				pinmux = <STM32_PINMUX('B', 14, AF7)>;
				drive-push-pull;
			};

			/omit-if-no-ref/ usart3_rts_pd2: usart3_rts_pd2 {
				pinmux = <STM32_PINMUX('D', 2, AF7)>;
				drive-push-pull;
			};

			/omit-if-no-ref/ uart4_rts_pa15: uart4_rts_pa15 {
				pinmux = <STM32_PINMUX('A', 15, AF8)>;
				drive-push-pull;
			};

			/omit-if-no-ref/ uart5_rts_pb4: uart5_rts_pb4 {
				pinmux = <STM32_PINMUX('B', 4, AF8)>;
				drive-push-pull;
			};

			/* UART_RX / USART_RX / LPUART_RX */

			/omit-if-no-ref/ lpuart1_rx_pa3: lpuart1_rx_pa3 {
				pinmux = <STM32_PINMUX('A', 3, AF8)>;
			};

			/omit-if-no-ref/ usart1_rx_pa10: usart1_rx_pa10 {
				pinmux = <STM32_PINMUX('A', 10, AF7)>;
			};

			/omit-if-no-ref/ usart1_rx_pb7: usart1_rx_pb7 {
				pinmux = <STM32_PINMUX('B', 7, AF7)>;
			};

			/omit-if-no-ref/ lpuart1_rx_pb10: lpuart1_rx_pb10 {
				pinmux = <STM32_PINMUX('B', 10, AF8)>;
			};

			/omit-if-no-ref/ lpuart1_rx_pc0: lpuart1_rx_pc0 {
				pinmux = <STM32_PINMUX('C', 0, AF8)>;
			};

			/omit-if-no-ref/ usart3_rx_pa5: usart3_rx_pa5 {
				pinmux = <STM32_PINMUX('A', 5, AF7)>;
			};

			/omit-if-no-ref/ usart3_rx_pc11: usart3_rx_pc11 {
				pinmux = <STM32_PINMUX('C', 11, AF7)>;
			};

			/omit-if-no-ref/ uart4_rx_pa1: uart4_rx_pa1 {
				pinmux = <STM32_PINMUX('A', 1, AF8)>;
			};

			/omit-if-no-ref/ uart4_rx_pc11: uart4_rx_pc11 {
				pinmux = <STM32_PINMUX('C', 11, AF8)>;
			};

			/omit-if-no-ref/ uart5_rx_pd2: uart5_rx_pd2 {
				pinmux = <STM32_PINMUX('D', 2, AF8)>;
			};

			/* UART_TX / USART_TX / LPUART_TX */

			/omit-if-no-ref/ lpuart1_tx_pa2: lpuart1_tx_pa2 {
				pinmux = <STM32_PINMUX('A', 2, AF8)>;
				bias-pull-up;
			};

			/omit-if-no-ref/ usart1_tx_pa9: usart1_tx_pa9 {
				pinmux = <STM32_PINMUX('A', 9, AF7)>;
				bias-pull-up;
			};

			/omit-if-no-ref/ usart1_tx_pb6: usart1_tx_pb6 {
				pinmux = <STM32_PINMUX('B', 6, AF7)>;
				bias-pull-up;
			};

			/omit-if-no-ref/ lpuart1_tx_pc1: lpuart1_tx_pc1 {
				pinmux = <STM32_PINMUX('C', 1, AF8)>;
				bias-pull-up;
			};

			/omit-if-no-ref/ usart3_tx_pa7: usart3_tx_pa7 {
				pinmux = <STM32_PINMUX('A', 7, AF7)>;
				bias-pull-up;
			};

			/omit-if-no-ref/ usart3_tx_pb10: usart3_tx_pb10 {
				pinmux = <STM32_PINMUX('B', 10, AF7)>;
				bias-pull-up;
			};

			/omit-if-no-ref/ usart3_tx_pc10: usart3_tx_pc10 {
				pinmux = <STM32_PINMUX('C', 10, AF7)>;
				bias-pull-up;
			};

			/omit-if-no-ref/ uart4_tx_pa0: uart4_tx_pa0 {
				pinmux = <STM32_PINMUX('A', 0, AF8)>;
				bias-pull-up;
			};

			/omit-if-no-ref/ uart4_tx_pc10: uart4_tx_pc10 {
				pinmux = <STM32_PINMUX('C', 10, AF8)>;
				bias-pull-up;
			};

			/omit-if-no-ref/ uart5_tx_pc12: uart5_tx_pc12 {
				pinmux = <STM32_PINMUX('C', 12, AF8)>;
				bias-pull-up;
			};

			/* USB */

			/omit-if-no-ref/ usb_dm_pa11: usb_dm_pa11 {
				pinmux = <STM32_PINMUX('A', 11, ANALOG)>;
			};

			/omit-if-no-ref/ usb_dp_pa12: usb_dp_pa12 {
				pinmux = <STM32_PINMUX('A', 12, ANALOG)>;
			};

			/omit-if-no-ref/ usb_noe_pa13: usb_noe_pa13 {
				pinmux = <STM32_PINMUX('A', 13, AF10)>;
			};

			/omit-if-no-ref/ usb_noe_pc9: usb_noe_pc9 {
				pinmux = <STM32_PINMUX('C', 9, AF10)>;
			};

		};
	};
};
